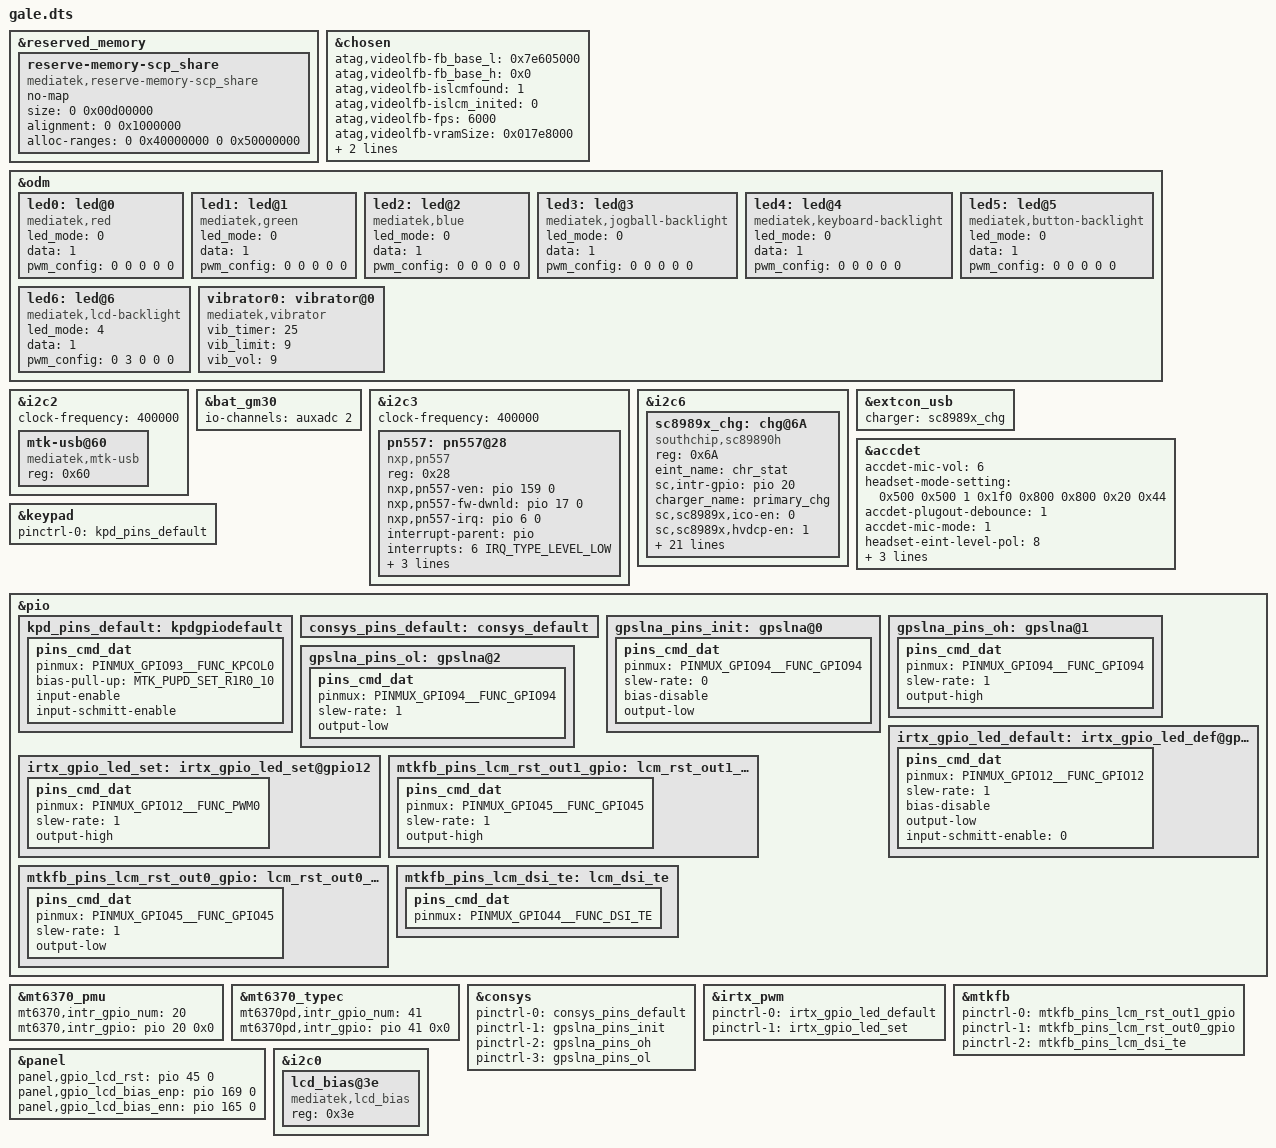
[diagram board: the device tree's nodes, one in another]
// SPDX-License-Identifier: GPL-2.0
/*
 * Copyright (c) 2019 MediaTek Inc.
 */

/dts-v1/;
/plugin/;
#include <dt-bindings/interrupt-controller/irq.h>
#include <dt-bindings/interrupt-controller/arm-gic.h>
#include <dt-bindings/pinctrl/mt6768-pinfunc.h>
#include "mediatek/touchscreen.dtsi"

&reserved_memory {
	reserve-memory-scp_share {
		compatible = "mediatek,reserve-memory-scp_share";
		no-map;
		size = <0 0x00d00000>;
		alignment = <0 0x1000000>;
		alloc-ranges = <0 0x40000000 0 0x50000000>;
	};
};

/* chosen */
&chosen {

	atag,videolfb-fb_base_l = <0x7e605000>;
	atag,videolfb-fb_base_h = <0x0>;
	atag,videolfb-islcmfound = <1>;
	atag,videolfb-islcm_inited = <0>;
	atag,videolfb-fps= <6000>;
	atag,videolfb-vramSize= <0x017e8000>;
	atag,videolfb-lcmname=
		"hx83112b_fhdp_dsi_cmd_auo_rt5081_drv";
};

&odm {
	led0:led@0 {
		compatible = "mediatek,red";
		led_mode = <0>;
		data = <1>;
		pwm_config = <0 0 0 0 0>;
	};
	led1:led@1 {
		compatible = "mediatek,green";
		led_mode = <0>;
		data = <1>;
		pwm_config = <0 0 0 0 0>;
	};
	led2:led@2 {
		compatible = "mediatek,blue";
		led_mode = <0>;
		data = <1>;
		pwm_config = <0 0 0 0 0>;
	};
	led3:led@3 {
		compatible = "mediatek,jogball-backlight";
		led_mode = <0>;
		data = <1>;
		pwm_config = <0 0 0 0 0>;
	};
	led4:led@4 {
		compatible = "mediatek,keyboard-backlight";
		led_mode = <0>;
		data = <1>;
		pwm_config = <0 0 0 0 0>;
	};
	led5:led@5 {
		compatible = "mediatek,button-backlight";
		led_mode = <0>;
		data = <1>;
		pwm_config = <0 0 0 0 0>;
	};
	led6:led@6 {
		compatible = "mediatek,lcd-backlight";
		led_mode = <4>;
		data = <1>;
		pwm_config = <0 3 0 0 0>;
	};
	vibrator0:vibrator@0 {
		compatible = "mediatek,vibrator";
		vib_timer = <25>;
		vib_limit = <9>;
		vib_vol= <9>;
	};
};

&i2c2 {
	clock-frequency = <400000>;

	mtk-usb@60 {
		compatible = "mediatek,mtk-usb";
		reg = <0x60>;
		status = "okay";
	};
};

&bat_gm30 {
	io-channels = <&auxadc 2>;
	io-channel-names = "batteryID-channel";
};

&i2c3 {
	status = "okay";
        clock-frequency = <400000>;
        pn557: pn557@28 {
		compatible = "nxp,pn557";
		reg = <0x28>;
		nxp,pn557-ven = <&pio 159 0>;
		nxp,pn557-fw-dwnld = <&pio 17 0>;
		nxp,pn557-irq = <&pio 6 0>;
		interrupt-parent = <&pio>;
		interrupts = <6 IRQ_TYPE_LEVEL_LOW>;
//add TMS NFC
		tms,irq-gpio        = <&pio 6 0x00>;
		tms,ven-gpio        = <&pio 159 0x0>;
		tms,download-gpio   = <&pio 17 0x0>;

		status = "okay";
        };
};

&i2c6 {
	status = "okay";
	sc8989x_chg: chg@6A {
			compatible = "southchip,sc89890h";
			reg = <0x6A>;
			eint_name = "chr_stat";
			sc,intr-gpio = <&pio 20 IRQ_TYPE_EDGE_FALLING>;
			charger_name = "primary_chg";
			sc,sc8989x,ico-en = <0>;
			sc,sc8989x,hvdcp-en = <1>;
			sc,sc8989x,auto-dpdm-en = <0>;
			sc,sc8989x,vsys-min = <5>; /*3500mV*/
			sc,sc8989x,vbatmin-sel = <0>; /*0:2.9V 1:2.5V*/
			sc,sc8989x,itrick = <3>; /*60 + val *60*/
			sc,sc8989x,iterm = <4>; /*30 + val * 60*/
			sc,sc8989x,vbat-cv = <38>; /*3840 + val * 16*/
			sc,sc8989x,vbat-low = <1>; /*0:2.8V 1:3V*/
			sc,sc8989x,vrechg = <0>; /*0:100mV 1:200mV*/
			sc,sc8989x,en-term = <1>;
			sc,sc8989x,stat-dis = <0>;
			sc,sc8989x,wd-time = <0>; /*0:Dis 1:40s 2:80s 3:160s*/
			sc,sc8989x,en-timer = <1>;
			sc,sc8989x,charge-timer = <2>; /*0:5h 1:8h 2:12h 3:20h*/
			sc,sc8989x,bat-comp = <0>; /*val * 20*/
			sc,sc8989x,vclamp = <0>; /*val *32*/
			sc,sc8989x,votg = <10>; /*3900 + val * 100*/
			sc,sc8989x,iboost = <7>; /*0:0.5A 3:1.4A 5:1.875A 7:2.45A*/
			sc,sc8989x,vindpm = <20>; /*2600 + val * 100*/

			/*bq25890*/
			bq,bq25890,votg = <7>; /*4550 + val * 64*/
			bq,bq25890,iterm = <3>; /*64 + val * 64*/
			bq,bq25890,itrick = <3>; /*64 + val *64*/
	};
};

&extcon_usb {
	charger = <&sc8989x_chg>;
};

/* accdet start */
&accdet {
	/* accdet micbias voltage: 0x07,2.7v;0x05,2.5v;0x02,1.9v */
	accdet-mic-vol = <6>;
	headset-mode-setting = <0x500 0x500 1 0x1f0 0x800 0x800 0x20 0x44>;
	accdet-plugout-debounce = <1>;
	/*1:ACC mode, 2:low cost without in bias, 6:low cost with in bias*/
	accdet-mic-mode = <1>;
	/* eint_level_trigger: 8,LEVEL_LOW(DEF) ;4,LV_HIGH;others,LV_LOW */
	headset-eint-level-pol = <8>;
	/*0--MD_MAX--UP_MAX--DW_MAX*/
	headset-three-key-threshold = <0 80 220 400>;
	headset-three-key-threshold-CDD = <0 121 192 600>;
	/*0--MD_MAX--VOICE_MAX--UP_MAX--DW_MAX*/
	headset-four-key-threshold = <0 58 121 192 400>;
	status = "okay";
};
/* accdet end */

/* keypad start */
&keypad {
	pinctrl-names = "default";
	pinctrl-0 = <&kpd_pins_default>;
};

&pio {
	kpd_pins_default: kpdgpiodefault {
		pins_cmd_dat {
			pinmux = <PINMUX_GPIO93__FUNC_KPCOL0>;
			bias-pull-up = <MTK_PUPD_SET_R1R0_10>;
			input-enable;
			input-schmitt-enable;
		};
	};
};
/* keypad end */

&mt6370_pmu {
	mt6370,intr_gpio_num = <20>; /* direct defined GPIO num */
	mt6370,intr_gpio = <&pio 20 0x0>;
};
&mt6370_typec {
	mt6370pd,intr_gpio_num = <41>; /* direct defined GPIO num */
	mt6370pd,intr_gpio = <&pio 41 0x0>;
};

/* CONSYS GPIO standardization */
&pio {
	consys_pins_default: consys_default {
	};
	gpslna_pins_init: gpslna@0 {
		pins_cmd_dat {
			pinmux = <PINMUX_GPIO94__FUNC_GPIO94>;
			slew-rate = <0>;
			bias-disable;
			output-low;
		};
	};
	gpslna_pins_oh: gpslna@1 {
		pins_cmd_dat {
			pinmux = <PINMUX_GPIO94__FUNC_GPIO94>;
			slew-rate = <1>;
			output-high;
		};
	};
	gpslna_pins_ol: gpslna@2 {
		pins_cmd_dat {
			pinmux = <PINMUX_GPIO94__FUNC_GPIO94>;
			slew-rate = <1>;
			output-low;
		};
	};
};
&consys {
	pinctrl-names = "default", "gps_lna_state_init",
		"gps_lna_state_oh", "gps_lna_state_ol";
	pinctrl-0 = <&consys_pins_default>;
	pinctrl-1 = <&gpslna_pins_init>;
	pinctrl-2 = <&gpslna_pins_oh>;
	pinctrl-3 = <&gpslna_pins_ol>;
	status = "okay";
};
/* CONSYS end */

/* IRTX GPIO Start */
&irtx_pwm {
	pinctrl-names = "irtx_gpio_led_default", "irtx_gpio_led_set";
	pinctrl-0 = <&irtx_gpio_led_default>;
	pinctrl-1 = <&irtx_gpio_led_set>;
	status = "okay";
};
&pio {
	/* IRTX GPIO Settings -Start */
	/* default: GPIO0, output, high */
	irtx_gpio_led_default:irtx_gpio_led_def@gpio12 {
		pins_cmd_dat {
			pinmux = <PINMUX_GPIO12__FUNC_GPIO12>;
			slew-rate = <1>;
			bias-disable;
			output-low;
			input-schmitt-enable = <0>;
		};
	};

	irtx_gpio_led_set:irtx_gpio_led_set@gpio12 {
		pins_cmd_dat {
			pinmux = <PINMUX_GPIO12__FUNC_PWM0>;
			slew-rate = <1>;
			output-high;
		};
	};
}; /* IRTX GPIO Settings -End */

/* DISPSYS GPIO standardization */
&pio {
	mtkfb_pins_lcm_rst_out1_gpio: lcm_rst_out1_gpio {
		pins_cmd_dat {
			pinmux = <PINMUX_GPIO45__FUNC_GPIO45>;
			slew-rate = <1>;
			output-high;
		};
	};

	mtkfb_pins_lcm_rst_out0_gpio: lcm_rst_out0_gpio {
		pins_cmd_dat {
			pinmux = <PINMUX_GPIO45__FUNC_GPIO45>;
			slew-rate = <1>;
			output-low;
		};
	};

	mtkfb_pins_lcm_dsi_te: lcm_dsi_te {
		pins_cmd_dat {
			pinmux = <PINMUX_GPIO44__FUNC_DSI_TE>;
		};
	};
};

&mtkfb {
	pinctrl-names =
		"lcm_rst_out1_gpio", "lcm_rst_out0_gpio",
		"mode_te_te";
	pinctrl-0 = <&mtkfb_pins_lcm_rst_out1_gpio>;
	pinctrl-1 = <&mtkfb_pins_lcm_rst_out0_gpio>;
	pinctrl-2 = <&mtkfb_pins_lcm_dsi_te>;
	status = "okay";
};

&panel{
	panel,gpio_lcd_rst = <&pio 45 0>;
	panel,gpio_lcd_bias_enp = <&pio 169 0>;
	panel,gpio_lcd_bias_enn = <&pio 165 0>;
};

&i2c0{

	lcd_bias@3e {
		compatible = "mediatek,lcd_bias";
		reg = <0x3e>;
		status = "okay";
	};
};

/* DISPSYS GPIO standardization end*/

#include <gale/cust.dtsi>
#include "mediatek/cust_mt6768_camera.dtsi"
//#include "mediatek/cust_mt6768_touch_1080x2160.dtsi"
#include "mediatek/foursemi-fs15xx.dtsi"
#include "mediatek/fingerprint.dtsi"
/*End of this file, DO NOT ADD ANYTHING HERE*/
